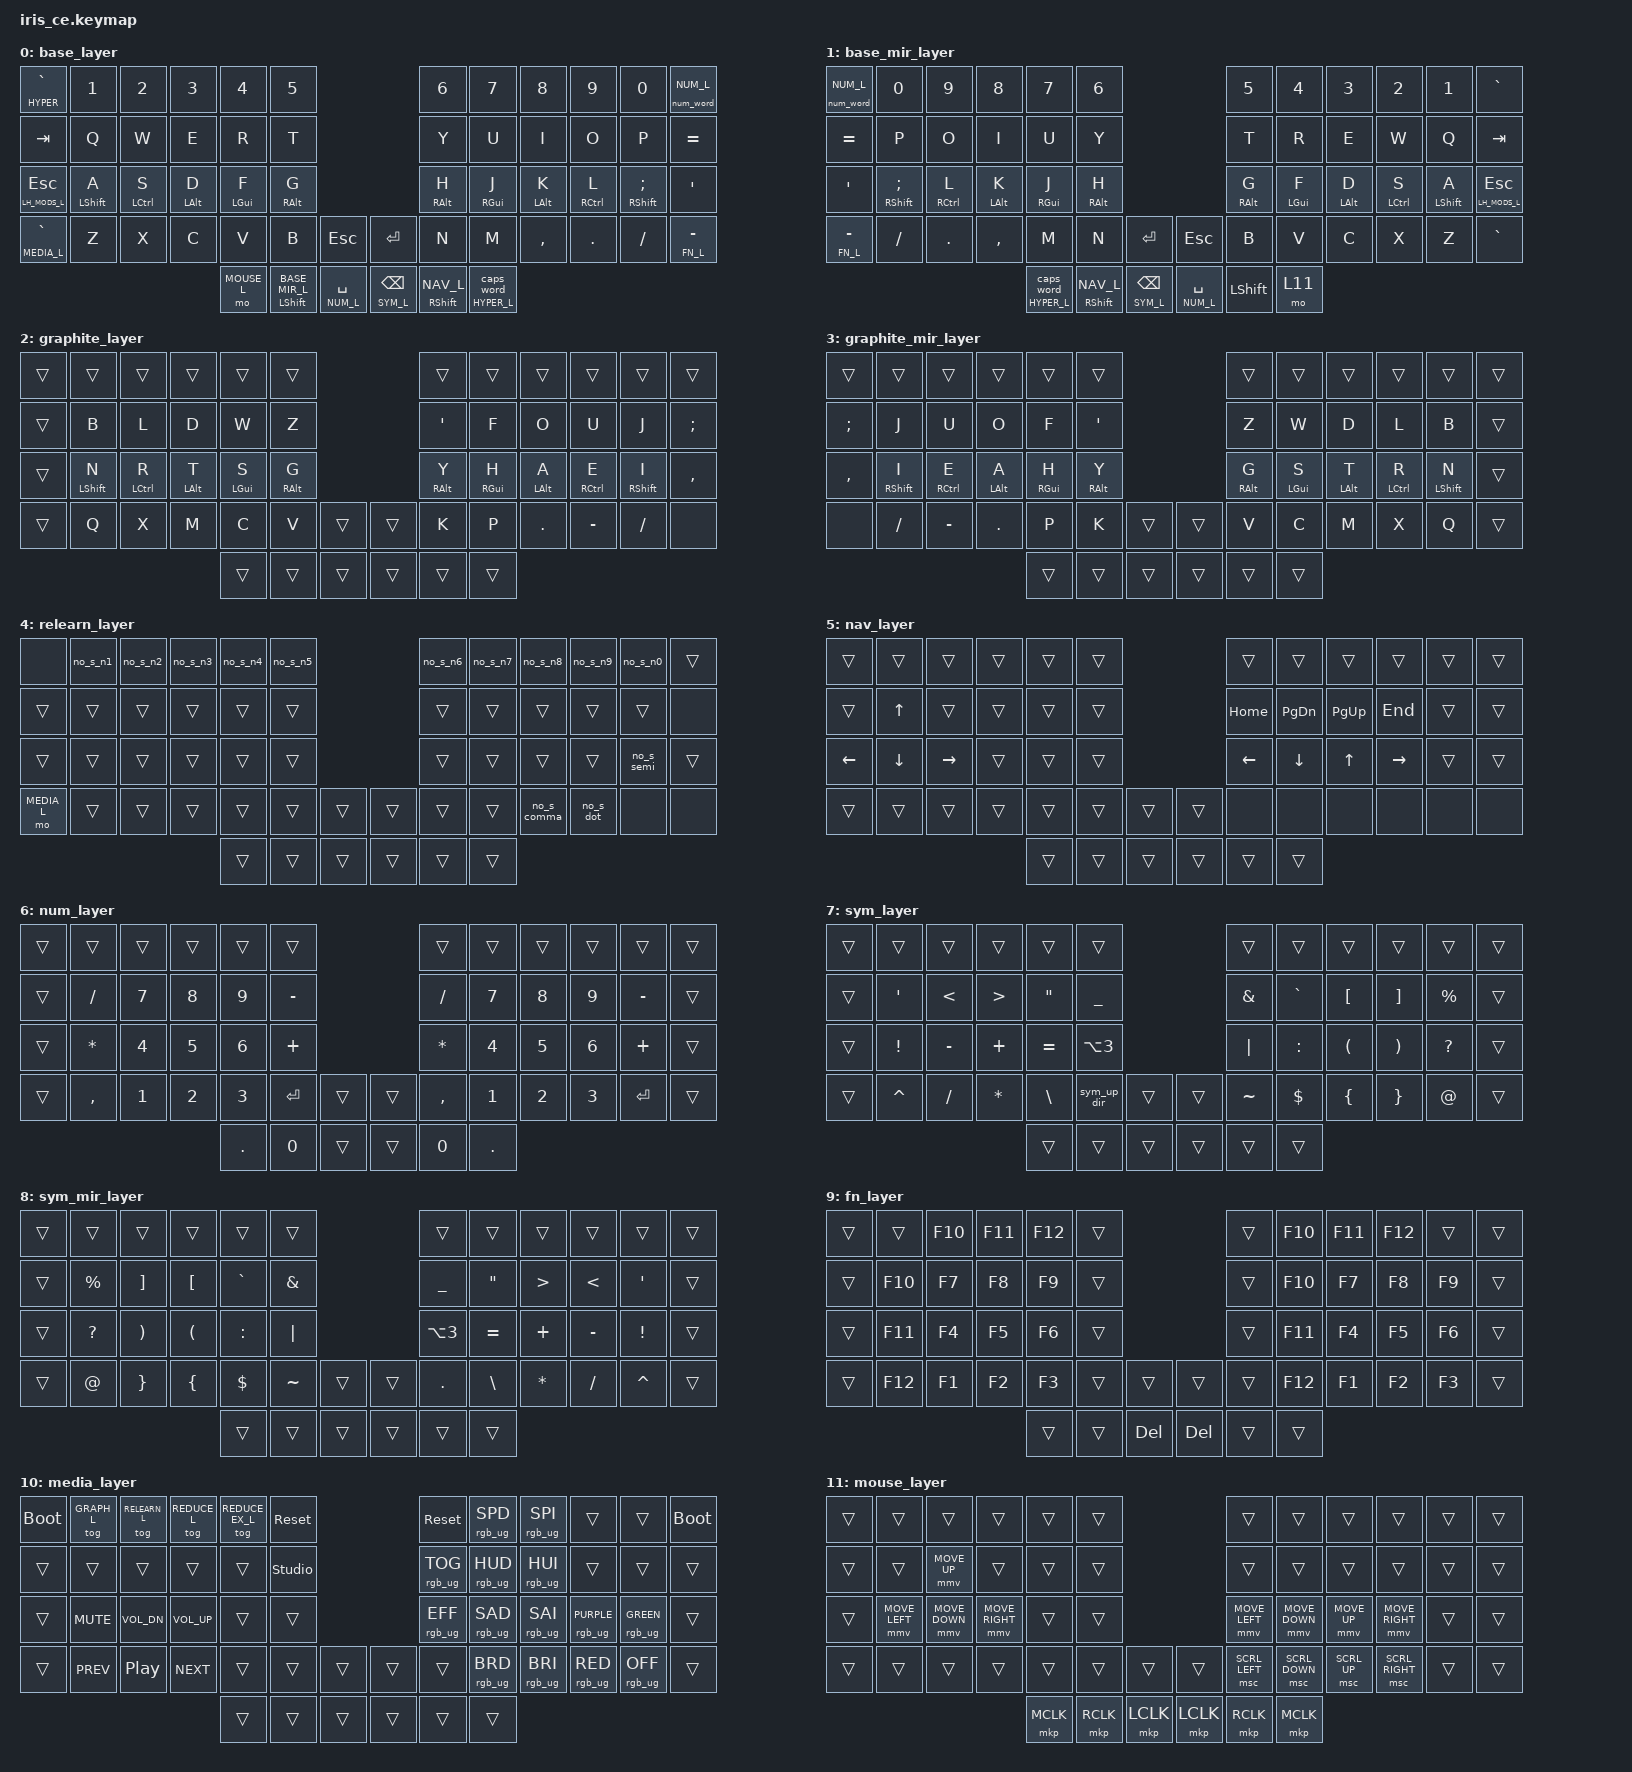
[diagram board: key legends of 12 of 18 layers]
/*
 * Copyright (c) 2024 The ZMK Contributors
 *
 * SPDX-License-Identifier: MIT
 */

#define ZMK_MOUSE_DEFAULT_MOVE_VAL 1500
#define ZMK_MOUSE_DEFAULT_SCRL_VAL 20

#include <behaviors/num_word.dtsi>
#include <behaviors.dtsi>
#include <dt-bindings/zmk/keys.h>
#include <dt-bindings/zmk/pointing.h>
#include <dt-bindings/zmk/rgb.h>

/* layers */

#define BASE_L       0
#define BASE_MIR_L   1
#define GRAPH_L      2
#define GRAPH_MIR_L  3
#define RELEARN_L    4
#define NAV_L        5
#define NUM_L        6
#define SYM_L        7
#define SYM_MIR_L    8
#define FN_L         9
#define MEDIA_L      10
#define MOUSE_L      11
#define HYPER_L      12
#define LH_MODS_L    13
#define RH_MODS_L    14
#define REDUCE_L     15
#define REDUCE_EX_L  16
#define BLOCK_L      17

/* keycode / value shorthands / don't use fn macros shorthands as they are not compatible with keyboard layout editor */

#define HYPER      LS(LC(LA(LGUI)))    /* hyper as a held modifier (mt) */
#define RGB_PURPLE RGB_COLOR_HSB(298, 100, 41)
#define RGB_GREEN  RGB_COLOR_HSB(150, 80, 5)
#define RGB_RED    RGB_COLOR_HSB(0, 100, 50)
#define RGB_OFF    RGB_COLOR_HSB(242, 0, 0)

/* positions */

#define LHK 0 1 2 3 4 5 12 13 14 15 16 17 24 25 26 27 28 29 36 37 38 39 40 41
#define LHT 50 51 52 42
#define RHK 6 7 8 9 10 11 18 19 20 21 22 23 30 31 32 33 34 35 44 45 46 47 48 49
#define RHT 53 54 55 43

&sk { release-after-ms = <1500>; };

&mmv {
    acceleration-exponent = <1>;
    time-to-max-speed-ms = <500>;
    delay-ms = <0>;
};

&msc {
    acceleration-exponent = <1>;
    time-to-max-speed-ms = <200>;
    delay-ms = <0>;
};

/* Emits a single mod-morph node; invoked inside the behaviors node below so all
   no_s_* behaviors share one node rather than each defining their own. */

#define ZMK_BLOCK_SHIFT(name, key) \
    no_s_##name: no_s_##name { \
        compatible = "zmk,behavior-mod-morph"; \
        bindings = <&kp key>, <&none>; \
        #binding-cells = <0>; \
        mods = <(MOD_LSFT|MOD_RSFT)>; \
    };

/ {
    combos {
        compatible = "zmk,combos";

        // cb_esc {
        //     bindings = <&kp ESCAPE>;
        //     key-positions = <15 16>;
        // };
        // cb_ret {
        //     bindings = <&kp RET>;
        //     key-positions = <20 19>;
        // };

        cut {
            bindings = <&kp LG(X)>;
            key-positions = <37 38>;
        };

        copy {
            bindings = <&kp LG(C)>;
            key-positions = <38 39>;
        };

        paste {
            bindings = <&kp LG(V)>;
            key-positions = <40 39>;
        };

        block {
            bindings = <&tog BLOCK_L>;
            key-positions = <0 11>;
        };
    };

    behaviors {
        startup_layers: startup_layers {
            compatible = "zmk,behavior-startup-layers";
            #binding-cells = <0>;
            startup-layers-list = <>;
        };

        ZMK_BLOCK_SHIFT(n1, N1)
        ZMK_BLOCK_SHIFT(n2, N2)
        ZMK_BLOCK_SHIFT(n3, N3)
        ZMK_BLOCK_SHIFT(n4, N4)
        ZMK_BLOCK_SHIFT(n5, N5)
        ZMK_BLOCK_SHIFT(n6, N6)
        ZMK_BLOCK_SHIFT(n7, N7)
        ZMK_BLOCK_SHIFT(n8, N8)
        ZMK_BLOCK_SHIFT(n9, N9)
        ZMK_BLOCK_SHIFT(n0, N0)
        ZMK_BLOCK_SHIFT(minus, MINUS)
        ZMK_BLOCK_SHIFT(equal, EQUAL)
        ZMK_BLOCK_SHIFT(semi, SEMI)
        ZMK_BLOCK_SHIFT(comma, COMMA)
        ZMK_BLOCK_SHIFT(dot, DOT)

        /* thumb hold tap - layer */

        tht: tht {
            compatible = "zmk,behavior-hold-tap";
            #binding-cells = <2>;
            flavor = "balanced";
            tapping-term-ms = <300>;
            require-prior-idle-ms = <350>;
            quick-tap-ms = <200>;
            bindings = <&mo>, <&kp>;

            hold-while-undecided;
        };

        tht_bspc: tht_bspc {
            compatible = "zmk,behavior-hold-tap";
            #binding-cells = <2>;
            flavor = "hold-preferred";
            tapping-term-ms = <300>;
            require-prior-idle-ms = <150>;
            quick-tap-ms = <200>;
            bindings = <&mo>, <&kp>;

            hold-while-undecided;
        };

        tht_caps: tht_caps {
            compatible = "zmk,behavior-hold-tap";
            #binding-cells = <2>;
            flavor = "hold-preferred";
            tapping-term-ms = <200>;
            bindings = <&mo>, <&caps_word>;

            require-prior-idle-ms = <300>;
            quick-tap-ms = <200>;
            hold-while-undecided;
        };

        tht_num: tht_num {
            compatible = "zmk,behavior-hold-tap";
            #binding-cells = <2>;
            flavor = "hold-preferred";
            tapping-term-ms = <200>;
            bindings = <&mo>, <&num_word>;

            require-prior-idle-ms = <300>;
            quick-tap-ms = <200>;
            hold-while-undecided;
        };

        vol_l: vol_l {
            compatible = "zmk,behavior-hold-tap";
            #binding-cells = <2>;
            bindings = <&kp>, <&mo>;

            flavor = "hold-preferred";
            tapping-term-ms = <1500>;
            quick-tap-ms = <200>;
            hold-trigger-key-positions = <RHK RHT>;
            hold-while-undecided;
        };

        vol_r: vol_r {
            compatible = "zmk,behavior-hold-tap";
            #binding-cells = <2>;
            bindings = <&kp>, <&mo>;

            flavor = "hold-preferred";
            hold-trigger-key-positions = <LHK LHT>;
            tapping-term-ms = <1500>;
        };

        vol_r_rep: vol_r_rep {
            compatible = "zmk,behavior-hold-tap";
            #binding-cells = <2>;
            bindings = <&mo>, <&key_repeat>;

            flavor = "hold-preferred";
            tapping-term-ms = <300>;
        };

        hrm_l: hrm_l {
            compatible = "zmk,behavior-hold-tap";
            bindings = <&kp>, <&kp>;

            #binding-cells = <2>;
            tapping-term-ms = <300>;
            flavor = "balanced";
            quick-tap-ms = <175>;
            require-prior-idle-ms = <150>;
            hold-trigger-on-release;
            hold-trigger-key-positions = <RHK RHT LHT>;
        };

        hrm_r: hrm_r {
            compatible = "zmk,behavior-hold-tap";
            bindings = <&kp>, <&kp>;

            #binding-cells = <2>;
            tapping-term-ms = <300>;
            flavor = "balanced";
            quick-tap-ms = <175>;
            require-prior-idle-ms = <150>;
            hold-trigger-on-release;
            hold-trigger-key-positions = <LHK LHT RHT>;
        };

        hrl_l: hrl_l {
            compatible = "zmk,behavior-hold-tap";
            #binding-cells = <2>;
            tapping-term-ms = <300>;
            flavor = "balanced";
            quick-tap-ms = <175>;
            require-prior-idle-ms = <150>;
            hold-trigger-on-release;
            hold-trigger-key-positions = <RHK RHT LHT>;
            bindings = <&mo>, <&kp>;
        };

        hrl_r: hrl_r {
            compatible = "zmk,behavior-hold-tap";
            #binding-cells = <2>;
            tapping-term-ms = <300>;
            flavor = "balanced";
            quick-tap-ms = <175>;
            require-prior-idle-ms = <150>;
            hold-trigger-on-release;
            hold-trigger-key-positions = <LHK LHT RHT>;
            bindings = <&mo>, <&kp>;
        };

        nwin: nwin {
            compatible = "zmk,behavior-tri-state";
            #binding-cells = <0>;
            bindings = <&kt LGUI>, <&kp TAB>, <&kt LGUI>;

            ignored-key-positions = <19>;
        };

        nav_word: nav_word {
            compatible = "zmk,behavior-auto-layer";
            #binding-cells = <1>;
            continue-list = <LEFT DOWN UP RIGHT PG_DN PG_UP>;
            ignore-modifiers;
        };

        sym_word: sym_word {
            compatible = "zmk,behavior-auto-layer";
            #binding-cells = <1>;
            continue-list = <SQT LT GT DQT UNDER EXCL MINUS PLUS EQUAL N3 CARET FSLH STAR BSLH AMPS PIPE GRAVE LBKT RBKT PRCNT PIPE COLON LPAR RPAR QMARK TILDE DLLR LBRC RBRC AT BSPC DEL SPC PERIOD SLASH>;
            ignore-modifiers;
        };

        td_num: td_num {
            compatible = "zmk,behavior-tap-dance";
            #binding-cells = <0>;
            tapping-term-ms = <400>;
            bindings = <&sl NUM_L>, <&num_word NUM_L>;
        };

        td_sym: td_sym {
            compatible = "zmk,behavior-tap-dance";
            #binding-cells = <0>;
            tapping-term-ms = <400>;
            bindings = <&sl SYM_L>, <&sym_word SYM_L>;
        };

        td_nav: td_nav {
            compatible = "zmk,behavior-tap-dance";
            #binding-cells = <0>;
            tapping-term-ms = <400>;
            bindings = <&sl NAV_L>, <&nav_word NAV_L>;
        };

        td_mir: td_mir {
            compatible = "zmk,behavior-tap-dance";
            #binding-cells = <0>;
            tapping-term-ms = <400>;
            bindings = <&sl BASE_MIR_L>, <&to BASE_MIR_L>;
        };
    };

    macros {
        sym_up_dir: sym_up_dir {
            compatible = "zmk,behavior-macro";
            #binding-cells = <0>;
            bindings = <&kp DOT &kp DOT &kp FSLH>;
        };

        sym_double_colon: sym_double_colon {
            compatible = "zmk,behavior-macro";
            #binding-cells = <0>;
            bindings = <&kp COLON &kp COLON>;
        };
    };

    keymap {
        compatible = "zmk,keymap";

        base_layer {
            bindings = <
&mt HYPER GRAVE     &kp N1          &kp N2          &kp N3         &kp N4         &kp N5                                                               &kp N6              &kp N7               &kp N8         &kp N9          &kp N0             &num_word NUM_L
&kp TAB             &kp Q           &kp W           &kp E          &kp R          &kp T                                                                &kp Y               &kp U                &kp I          &kp O           &kp P              &kp EQUAL
&lt LH_MODS_L ESC   &hrm_l LSHFT A  &hrm_l LCTRL S  &hrm_l LALT D  &hrm_l LGUI F  &hrm_l RALT G                                                        &hrm_r RALT H       &hrm_r RGUI J        &hrm_r LALT K  &hrm_r RCTRL L  &hrm_r RSHFT SEMI  &kp SQT
&tht MEDIA_L GRAVE  &kp Z           &kp X           &kp C          &kp V          &kp B                    &kp ESC             &kp ENTER             &kp N               &kp M                &kp COMMA      &kp DOT         &kp SLASH          &tht FN_L MINUS
                                                                   &mo MOUSE_L    &vol_l LSHFT BASE_MIR_L  &tht NUM_L SPACE    &tht_bspc SYM_L BSPC  &vol_r RSHFT NAV_L  &tht_caps HYPER_L 0
            >;
        };

        base_mir_layer {
            bindings = <
&num_word NUM_L  &kp N0             &kp N9          &kp N8         &kp N7               &kp N6                                                          &kp N5         &kp N4         &kp N3         &kp N2          &kp N1          &kp GRAVE
&kp EQUAL        &kp P              &kp O           &kp I          &kp U                &kp Y                                                           &kp T          &kp R          &kp E          &kp W           &kp Q           &kp TAB
&kp SQT          &hrm_l RSHFT SEMI  &hrm_l RCTRL L  &hrm_l LALT K  &hrm_l RGUI J        &hrm_l RALT H                                                   &hrm_r RALT G  &hrm_r LGUI F  &hrm_r LALT D  &hrm_r LCTRL S  &hrm_r LSHFT A  &lt LH_MODS_L ESC
&tht FN_L MINUS  &kp SLASH          &kp DOT         &kp COMMA      &kp M                &kp N               &kp RET                 &kp ESC             &kp B          &kp V          &kp C          &kp X           &kp Z           &kp GRAVE
                                                                   &tht_caps HYPER_L 0  &vol_l RSHFT NAV_L  &tht_bspc SYM_L BSPC    &tht NUM_L SPACE    &kp LSHFT      &mo 11
            >;
        };

        graphite_layer {
            bindings = <
&trans  &trans          &trans          &trans         &trans         &trans                           &trans         &trans         &trans         &trans          &trans          &trans
&trans  &kp B           &kp L           &kp D          &kp W          &kp Z                            &kp SQT        &kp F          &kp O          &kp U           &kp J           &kp SEMI
&trans  &hrm_l LSHFT N  &hrm_l LCTRL R  &hrm_l LALT T  &hrm_l LGUI S  &hrm_l RALT G                    &hrm_r RALT Y  &hrm_r RGUI H  &hrm_r LALT A  &hrm_r RCTRL E  &hrm_r RSHFT I  &kp COMMA
&trans  &kp Q           &kp X           &kp M          &kp C          &kp V          &trans    &trans  &kp K          &kp P          &kp DOT        &kp MINUS       &kp SLASH       &none
                                                       &trans         &trans         &trans    &trans  &trans         &trans
            >;
        };

        graphite_mir_layer {
            bindings = <
&trans     &trans          &trans          &trans         &trans         &trans                           &trans         &trans         &trans         &trans          &trans          &trans
&kp SEMI   &kp J           &kp U           &kp O          &kp F          &kp SQT                          &kp Z          &kp W          &kp D          &kp L           &kp B           &trans
&kp COMMA  &hrm_l RSHFT I  &hrm_l RCTRL E  &hrm_l LALT A  &hrm_l RGUI H  &hrm_l RALT Y                    &hrm_r RALT G  &hrm_r LGUI S  &hrm_r LALT T  &hrm_r LCTRL R  &hrm_r LSHFT N  &trans
&none      &kp SLASH       &kp MINUS       &kp DOT        &kp P          &kp K          &trans    &trans  &kp V          &kp C          &kp M          &kp X           &kp Q           &trans
                                                          &trans         &trans         &trans    &trans  &trans         &trans
            >;
        };

        relearn_layer {
            bindings = <
&none        &no_s_n1  &no_s_n2  &no_s_n3  &no_s_n4  &no_s_n5                    &no_s_n6  &no_s_n7  &no_s_n8     &no_s_n9   &no_s_n0    &trans
&trans       &trans    &trans    &trans    &trans    &trans                      &trans    &trans    &trans       &trans     &trans      &none
&trans       &trans    &trans    &trans    &trans    &trans                      &trans    &trans    &trans       &trans     &no_s_semi  &trans
&mo MEDIA_L  &trans    &trans    &trans    &trans    &trans    &trans    &trans  &trans    &trans    &no_s_comma  &no_s_dot  &none       &none
                                           &trans    &trans    &trans    &trans  &trans    &trans
            >;
        };

        nav_layer {
            bindings = <
&trans    &trans    &trans     &trans  &trans  &trans                    &trans    &trans     &trans     &trans     &trans  &trans
&trans    &kp UP    &trans     &trans  &trans  &trans                    &kp HOME  &kp PG_DN  &kp PG_UP  &kp END    &trans  &trans
&kp LEFT  &kp DOWN  &kp RIGHT  &trans  &trans  &trans                    &kp LEFT  &kp DOWN   &kp UP     &kp RIGHT  &trans  &trans
&trans    &trans    &trans     &trans  &trans  &trans  &trans    &trans  &none     &none      &none      &none      &none   &none
                                       &trans  &trans  &trans    &trans  &trans    &trans
            >;
        };

        num_layer {
            bindings = <
&trans  &trans     &trans  &trans  &trans   &trans                       &trans     &trans   &trans  &trans  &trans     &trans
&trans  &kp FSLH   &kp N7  &kp N8  &kp N9   &kp MINUS                    &kp FSLH   &kp N7   &kp N8  &kp N9  &kp MINUS  &trans
&trans  &kp STAR   &kp N4  &kp N5  &kp N6   &kp PLUS                     &kp STAR   &kp N4   &kp N5  &kp N6  &kp PLUS   &trans
&trans  &kp COMMA  &kp N1  &kp N2  &kp N3   &kp RET    &trans    &trans  &kp COMMA  &kp N1   &kp N2  &kp N3  &kp RET    &trans
                                   &kp DOT  &kp N0     &trans    &trans  &kp N0     &kp DOT
            >;
        };

        sym_layer {
            bindings = <
&trans  &trans     &trans     &trans    &trans     &trans                         &trans     &trans     &trans    &trans    &trans     &trans
&trans  &kp SQT    &kp LT     &kp GT    &kp DQT    &kp UNDER                      &kp AMPS   &kp GRAVE  &kp LBKT  &kp RBKT  &kp PRCNT  &trans
&trans  &kp EXCL   &kp MINUS  &kp PLUS  &kp EQUAL  &kp LA(N3)                     &kp PIPE   &kp COLON  &kp LPAR  &kp RPAR  &kp QMARK  &trans
&trans  &kp CARET  &kp FSLH   &kp STAR  &kp BSLH   &sym_up_dir  &trans    &trans  &kp TILDE  &kp DLLR   &kp LBRC  &kp RBRC  &kp AT     &trans
                                        &trans     &trans       &trans    &trans  &trans     &trans
            >;
        };

        sym_mir_layer {
            bindings = <
&trans  &trans     &trans    &trans    &trans     &trans                       &trans      &trans     &trans    &trans     &trans     &trans
&trans  &kp PRCNT  &kp RBKT  &kp LBKT  &kp GRAVE  &kp AMPS                     &kp UNDER   &kp DQT    &kp GT    &kp LT     &kp SQT    &trans
&trans  &kp QMARK  &kp RPAR  &kp LPAR  &kp COLON  &kp PIPE                     &kp LA(N3)  &kp EQUAL  &kp PLUS  &kp MINUS  &kp EXCL   &trans
&trans  &kp AT     &kp RBRC  &kp LBRC  &kp DLLR   &kp TILDE  &trans    &trans  &kp DOT     &kp BSLH   &kp STAR  &kp FSLH   &kp CARET  &trans
                                       &trans     &trans     &trans    &trans  &trans      &trans
            >;
        };

        fn_layer {
            bindings = <
&trans  &trans   &kp F10  &kp F11  &kp F12  &trans                      &trans  &kp F10  &kp F11  &kp F12  &trans  &trans
&trans  &kp F10  &kp F7   &kp F8   &kp F9   &trans                      &trans  &kp F10  &kp F7   &kp F8   &kp F9  &trans
&trans  &kp F11  &kp F4   &kp F5   &kp F6   &trans                      &trans  &kp F11  &kp F4   &kp F5   &kp F6  &trans
&trans  &kp F12  &kp F1   &kp F2   &kp F3   &trans  &trans     &trans   &trans  &kp F12  &kp F1   &kp F2   &kp F3  &trans
                                   &trans   &trans  &kp DEL    &kp DEL  &trans  &trans
            >;
        };

        media_layer {
            bindings = <
&bootloader  &tog GRAPH_L  &tog RELEARN_L  &tog REDUCE_L  &tog REDUCE_EX_L  &sys_reset                        &sys_reset       &rgb_ug RGB_SPD  &rgb_ug RGB_SPI  &trans              &trans             &bootloader
&trans       &trans        &trans          &trans         &trans            &studio_unlock                    &rgb_ug RGB_TOG  &rgb_ug RGB_HUD  &rgb_ug RGB_HUI  &trans              &trans             &trans
&trans       &kp C_MUTE    &kp C_VOL_DN    &kp C_VOL_UP   &trans            &trans                            &rgb_ug RGB_EFF  &rgb_ug RGB_SAD  &rgb_ug RGB_SAI  &rgb_ug RGB_PURPLE  &rgb_ug RGB_GREEN  &trans
&trans       &kp C_PREV    &kp C_PP        &kp C_NEXT     &trans            &trans          &trans    &trans  &trans           &rgb_ug RGB_BRD  &rgb_ug RGB_BRI  &rgb_ug RGB_RED     &rgb_ug RGB_OFF    &trans
                                                          &trans            &trans          &trans    &trans  &trans           &trans
            >;
        };

        mouse_layer {
            bindings = <
&trans  &trans          &trans          &trans           &trans     &trans                             &trans          &trans          &trans        &trans           &trans  &trans
&trans  &trans          &mmv MOVE_UP    &trans           &trans     &trans                             &trans          &trans          &trans        &trans           &trans  &trans
&trans  &mmv MOVE_LEFT  &mmv MOVE_DOWN  &mmv MOVE_RIGHT  &trans     &trans                             &mmv MOVE_LEFT  &mmv MOVE_DOWN  &mmv MOVE_UP  &mmv MOVE_RIGHT  &trans  &trans
&trans  &trans          &trans          &trans           &trans     &trans     &trans       &trans     &msc SCRL_LEFT  &msc SCRL_DOWN  &msc SCRL_UP  &msc SCRL_RIGHT  &trans  &trans
                                                         &mkp MCLK  &mkp RCLK  &mkp LCLK    &mkp LCLK  &mkp RCLK       &mkp MCLK
            >;
        };

        hyper_layer {
            bindings = <
&trans  &kp LG(LA(LC(LS(N1))))  &kp LG(LA(LC(LS(N2))))  &kp LG(LA(LC(LS(N3))))  &kp LG(LA(LC(LS(N4))))  &kp LG(LA(LC(LS(N5))))                    &kp LG(LA(LC(LS(N6))))    &kp LG(LA(LC(LS(N7))))    &kp LG(LA(LC(LS(N8))))  &kp LG(LA(LC(LS(N9))))     &kp LG(LA(LC(LS(N0))))  &trans
&trans  &trans                  &trans                  &trans                  &trans                  &trans                                    &trans                    &kp LS(TAB)               &nwin                   &trans                     &trans                  &trans
&trans  &trans                  &trans                  &trans                  &trans                  &trans                                    &kp LG(LA(LC(LS(LEFT))))  &kp LG(LA(LC(LS(DOWN))))  &kp LG(LA(LC(LS(UP))))  &kp LG(LA(LC(LS(RIGHT))))  &trans                  &trans
&trans  &trans                  &trans                  &trans                  &trans                  &trans                  &trans    &trans  &trans                    &trans                    &trans                  &trans                     &trans                  &trans
                                                                                &trans                  &trans                  &trans    &trans  &trans                    &trans
            >;
        };

        lh_mods_layer {
            bindings = <
&none  &none           &none      &none     &none     &none                      &trans  &trans  &trans  &trans  &trans  &trans
&none  &none           &none      &none     &none     &none                      &trans  &trans  &trans  &trans  &trans  &trans
&none  &sk LSHFT       &sk LCTRL  &sk LALT  &sk LGUI  &sk RALT                   &trans  &trans  &trans  &trans  &trans  &trans
&none  &none           &td_nav    &td_sym   &td_num   &none    &none    &trans   &trans  &trans  &trans  &trans  &trans  &trans
                                            &none     &td_mir  &trans   &trans   &td_mir &none
            >;
        };

        rh_mods_layer {
            bindings = <
&trans  &trans  &trans  &trans  &trans  &trans                    &none     &none     &none     &none      &none          &none
&trans  &trans  &trans  &trans  &trans  &trans                    &none     &none     &none     &none      &none          &none
&trans  &trans  &trans  &trans  &trans  &trans                    &sk RALT  &sk RGUI  &sk LALT  &sk RCTRL  &sk RSHFT      &none
&trans  &trans  &trans  &trans  &trans  &trans   &trans    &none  &none     &td_num   &td_sym   &td_nav    &none          &none
                                &trans  &td_mir  &trans    &none  &td_mir   &none
            >;
        };

        reduce_layer {
           bindings = <
&none   &none   &none   &none   &none   &none                     &none   &none   &none   &none   &none   &none
&trans  &trans  &trans  &trans  &trans  &trans                    &trans  &trans  &trans  &trans  &trans  &trans
&trans  &trans  &trans  &trans  &trans  &trans                    &trans  &trans  &trans  &trans  &trans  &trans
&trans  &trans  &trans  &trans  &trans  &trans  &trans    &trans  &trans  &trans  &trans  &trans  &trans  &trans
                                &trans  &trans  &trans    &trans  &trans  &trans
            >;
        };

        reduce_ex_layer {
            bindings = <
&none  &none   &none   &none   &none   &none                     &none   &none   &none   &none   &none   &none
&none  &trans  &trans  &trans  &trans  &trans                    &trans  &trans  &trans  &trans  &trans  &none
&none  &trans  &trans  &trans  &trans  &trans                    &trans  &trans  &trans  &trans  &trans  &none
&none  &trans  &trans  &trans  &trans  &trans  &none     &none   &trans  &trans  &trans  &trans  &trans  &none
                               &trans  &trans  &trans    &trans  &trans  &trans
            >;
        };

        block_layer {
            bindings = <
&none  &none  &none  &none  &none  &none                  &none  &none  &none  &none  &none  &none
&none  &none  &none  &none  &none  &none                  &none  &none  &none  &none  &none  &none
&none  &none  &none  &none  &none  &none                  &none  &none  &none  &none  &none  &none
&none  &none  &none  &none  &none  &none  &none    &none  &none  &none  &none  &none  &none  &none
                            &none  &none  &none    &none  &none  &none
            >;
        };
    };

    conditional_layers {
        compatible = "zmk,conditional-layers";

        graphite_mir {
            if-layers = <BASE_MIR_L GRAPH_L>;
            then-layer = <GRAPH_MIR_L>;
        };

        sym_mir {
            if-layers = <BASE_MIR_L SYM_L>;
            then-layer = <SYM_MIR_L>;
        };

        mods {
            if-layers = <LH_MODS_L>;
            then-layer = <RH_MODS_L>;
        };
    };
};
